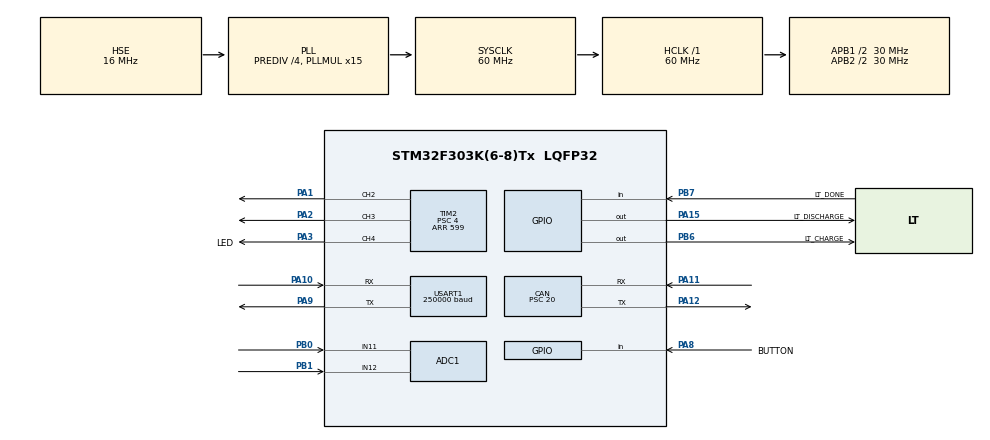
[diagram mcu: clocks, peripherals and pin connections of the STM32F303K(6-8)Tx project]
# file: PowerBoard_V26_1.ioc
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ADC1.Channel-0\#ChannelRegularConversion=ADC_CHANNEL_11
ADC1.Channel-1\#ChannelRegularConversion=ADC_CHANNEL_12
ADC1.Channel-2\#ChannelRegularConversion=ADC_CHANNEL_TEMPSENSOR
ADC1.ClockPrescaler=ADC_CLOCK_SYNC_PCLK_DIV4
ADC1.ContinuousConvMode=ENABLE
ADC1.DMAContinuousRequests=ENABLE
ADC1.NbrOfConversion=3
ADC1.NbrOfConversionFlag=1
ADC1.Offset-0\#ChannelRegularConversion=0
ADC1.Offset-1\#ChannelRegularConversion=0
ADC1.Offset-2\#ChannelRegularConversion=0
ADC1.OffsetNumber-0\#ChannelRegularConversion=ADC_OFFSET_NONE
ADC1.OffsetNumber-1\#ChannelRegularConversion=ADC_OFFSET_NONE
ADC1.OffsetNumber-2\#ChannelRegularConversion=ADC_OFFSET_NONE
ADC1.Rank-0\#ChannelRegularConversion=1
ADC1.Rank-1\#ChannelRegularConversion=2
ADC1.Rank-2\#ChannelRegularConversion=3
ADC1.SamplingTime-0\#ChannelRegularConversion=ADC_SAMPLETIME_19CYCLES_5
ADC1.SamplingTime-1\#ChannelRegularConversion=ADC_SAMPLETIME_19CYCLES_5
ADC1.SamplingTime-2\#ChannelRegularConversion=ADC_SAMPLETIME_61CYCLES_5
ADC1.SamplingTimeOPAMP-1\#ChannelRegularConversion=ADC_SAMPLETIME_61CYCLES_5
ADC1.SamplingTimeOPAMP-2\#ChannelRegularConversion=ADC_SAMPLETIME_61CYCLES_5
ADC1.master=1
CAN.BS1=CAN_BS1_12TQ
CAN.AutoBusOff=ENABLE
CAN.BS2=CAN_BS2_2TQ
CAN.CalculateBaudRate=99999
CAN.CalculateTimeBit=10000
CAN.CalculateTimeQuantum=666.6666666666667
CAN.Prescaler=20
CAN.SJW=CAN_SJW_2TQ
Dma.ADC1.0.Direction=DMA_PERIPH_TO_MEMORY
Dma.ADC1.0.Instance=DMA1_Channel1
Dma.ADC1.0.MemDataAlignment=DMA_MDATAALIGN_HALFWORD
Dma.ADC1.0.MemInc=DMA_MINC_ENABLE
Dma.ADC1.0.Mode=DMA_CIRCULAR
Dma.ADC1.0.PeriphDataAlignment=DMA_PDATAALIGN_HALFWORD
Dma.ADC1.0.PeriphInc=DMA_PINC_DISABLE
Dma.ADC1.0.Priority=DMA_PRIORITY_LOW
Dma.Request0=ADC1
Mcu.Family=STM32F3
Mcu.Name=STM32F303K(6-8)Tx
Mcu.Package=LQFP32
NVIC.CAN_RX0_IRQn=true\:0\:0\:false\:false\:true\:true\:true\:true
NVIC.CAN_TX_IRQn=true\:0\:0\:false\:false\:true\:true\:true\:true
NVIC.DMA1_Channel1_IRQn=true\:0\:0\:false\:false\:true\:false\:true\:true
NVIC.PriorityGroup=NVIC_PRIORITYGROUP_4
PA1.Signal=S_TIM2_CH2
PA10.Mode=Asynchronous
PA10.Signal=USART1_RX
PA11.Mode=CAN_Activate
PA11.Signal=CAN_RX
PA12.Mode=CAN_Activate
PA12.Signal=CAN_TX
PA13.Mode=Serial_Wire
PA13.Signal=SYS_JTMS-SWDIO
PA14.Mode=Serial_Wire
PA14.Signal=SYS_JTCK-SWCLK
PA15.GPIO_Label=LT_DISCHARGE
PA15.Signal=GPIO_Output
PA2.Signal=S_TIM2_CH3
PA3.GPIO_Label=LED
PA3.Signal=S_TIM2_CH4
PA8.GPIO_Label=BUTTON
PA8.GPIO_PuPd=GPIO_PULLUP
PA8.Signal=GPIO_Input
PA9.Mode=Asynchronous
PA9.Signal=USART1_TX
PB0.Mode=IN11-Single-Ended
PB0.Signal=ADC1_IN11
PB1.Mode=IN12-Single-Ended
PB1.Signal=ADC1_IN12
PB6.GPIO_Label=LT_CHARGE
PB6.Signal=GPIO_Output
PB7.GPIO_Label=LT_DONE
PB7.Signal=GPIO_Input
PF0\ /\ OSC_IN.Mode=HSE-External-Oscillator
PF0\ /\ OSC_IN.Signal=RCC_OSC_IN
PF1\ /\ OSC_OUT.Mode=HSE-External-Oscillator
PF1\ /\ OSC_OUT.Signal=RCC_OSC_OUT
ProjectManager.HeapSize=0x200
ProjectManager.StackSize=0x400
ProjectManager.TargetToolchain=Makefile
RCC.AHBFreq_Value=60000000
RCC.APB1CLKDivider=RCC_HCLK_DIV2
RCC.APB1Freq_Value=30000000
RCC.APB1TimFreq_Value=60000000
RCC.APB2CLKDivider=RCC_HCLK_DIV2
RCC.APB2Freq_Value=30000000
RCC.APB2TimFreq_Value=60000000
RCC.CortexFreq_Value=60000000
RCC.HCLKFreq_Value=60000000
RCC.HSE_VALUE=16000000
RCC.HSI_VALUE=8000000
RCC.PLLMUL=RCC_PLL_MUL15
RCC.PLLSourceVirtual=RCC_PLLSOURCE_HSE
RCC.RCC_PLLsource_Clock_Source_FROM_HSE=RCC_HSE_PREDIV_DIV4
RCC.SYSCLKFreq_VALUE=60000000
RCC.SYSCLKSourceVirtual=RCC_SYSCLKSOURCE_PLLCLK
SH.S_TIM2_CH2.0=TIM2_CH2,PWM Generation2 CH2
SH.S_TIM2_CH3.0=TIM2_CH3,PWM Generation3 CH3
SH.S_TIM2_CH4.0=TIM2_CH4,PWM Generation4 CH4
TIM2.Channel-PWM\ Generation2\ CH2=TIM_CHANNEL_2
TIM2.Channel-PWM\ Generation3\ CH3=TIM_CHANNEL_3
TIM2.Channel-PWM\ Generation4\ CH4=TIM_CHANNEL_4
TIM2.Period=599
TIM2.Prescaler=4
USART1.BaudRate=250000
USART1.VirtualMode-Asynchronous=VM_ASYNC
VP_ADC1_TempSens_Input.Mode=IN-TempSens
board=custom

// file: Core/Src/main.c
/* USER CODE BEGIN Header */
/**
 ******************************************************************************
 * @file           : main.c
 * @brief          : Main program body
 ******************************************************************************
 * @attention
 *
 * Copyright (c) 2026 STMicroelectronics.
 * All rights reserved.
 *
 * This software is licensed under terms that can be found in the LICENSE file
 * in the root directory of this software component.
 * If no LICENSE file comes with this software, it is provided AS-IS.
 *
 ******************************************************************************
 */
/* USER CODE END Header */
#include "main.h"
#include "adc.h"
#include "can.h"
#include "dma.h"
#include "tim.h"
#include "usart.h"
#include "gpio.h"

/* USER CODE BEGIN Includes */
#include "app.h"
#include "iwdg.h"

/* USER CODE END Includes */

void SystemClock_Config(void);

/* USER CODE BEGIN 0 */
int _write(int file, char* ptr, int len) {
  HAL_UART_Transmit(&huart1, (uint8_t*)ptr, len, 10);
  return len;
}
/* USER CODE END 0 */

int main(void)
{

  /* MCU Configuration--------------------------------------------------------*/

  /* Reset of all peripherals, Initializes the Flash interface and the Systick. */
  HAL_Init();

  /* Configure the system clock */
  SystemClock_Config();

  /* Initialize all configured peripherals */
  MX_GPIO_Init();
  MX_DMA_Init();
  MX_TIM2_Init();
  MX_USART1_UART_Init();
  MX_CAN_Init();
  MX_ADC1_Init();
  /* USER CODE BEGIN 2 */
  MX_IWDG_Init();  // .iocでは未設定のため、再生成で消えないようUSER CODE内で呼ぶ

  /* USER CODE END 2 */

  /* Infinite loop */
  /* USER CODE BEGIN WHILE */
  Setup();
  MainApp();
  while (1) {
    /* USER CODE END WHILE */

  }
}

void SystemClock_Config(void)
{
  RCC_OscInitTypeDef RCC_OscInitStruct = {0};
  RCC_ClkInitTypeDef RCC_ClkInitStruct = {0};
  RCC_PeriphCLKInitTypeDef PeriphClkInit = {0};

  /** Initializes the RCC Oscillators according to the specified parameters
  * in the RCC_OscInitTypeDef structure.
  */
  RCC_OscInitStruct.OscillatorType = RCC_OSCILLATORTYPE_HSI|RCC_OSCILLATORTYPE_HSE
                              |RCC_OSCILLATORTYPE_LSI;
  RCC_OscInitStruct.HSEState = RCC_HSE_ON;
  RCC_OscInitStruct.HSEPredivValue = RCC_HSE_PREDIV_DIV4;
  RCC_OscInitStruct.HSIState = RCC_HSI_ON;
  RCC_OscInitStruct.HSICalibrationValue = RCC_HSICALIBRATION_DEFAULT;
  RCC_OscInitStruct.LSIState = RCC_LSI_ON;
  RCC_OscInitStruct.PLL.PLLState = RCC_PLL_ON;
  RCC_OscInitStruct.PLL.PLLSource = RCC_PLLSOURCE_HSE;
  RCC_OscInitStruct.PLL.PLLMUL = RCC_PLL_MUL15;
  if (HAL_RCC_OscConfig(&RCC_OscInitStruct) != HAL_OK)
  {
    Error_Handler();
  }

  /** Initializes the CPU, AHB and APB buses clocks
  */
  RCC_ClkInitStruct.ClockType = RCC_CLOCKTYPE_HCLK|RCC_CLOCKTYPE_SYSCLK
                              |RCC_CLOCKTYPE_PCLK1|RCC_CLOCKTYPE_PCLK2;
  RCC_ClkInitStruct.SYSCLKSource = RCC_SYSCLKSOURCE_PLLCLK;
  RCC_ClkInitStruct.AHBCLKDivider = RCC_SYSCLK_DIV1;
  RCC_ClkInitStruct.APB1CLKDivider = RCC_HCLK_DIV2;
  RCC_ClkInitStruct.APB2CLKDivider = RCC_HCLK_DIV2;

  if (HAL_RCC_ClockConfig(&RCC_ClkInitStruct, FLASH_LATENCY_2) != HAL_OK)
  {
    Error_Handler();
  }
  PeriphClkInit.PeriphClockSelection = RCC_PERIPHCLK_USART1;
  PeriphClkInit.Usart1ClockSelection = RCC_USART1CLKSOURCE_PCLK1;
  if (HAL_RCCEx_PeriphCLKConfig(&PeriphClkInit) != HAL_OK)
  {
    Error_Handler();
  }
}

void Error_Handler(void)
{
  __disable_irq();
  while (1) {
  }
}
